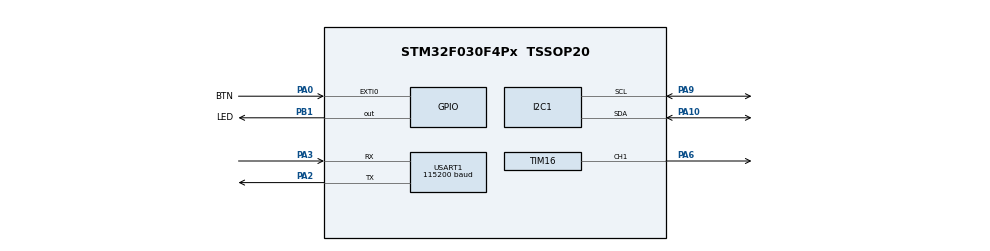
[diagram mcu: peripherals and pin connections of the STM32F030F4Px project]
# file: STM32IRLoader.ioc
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Dma.Request0=TIM16_CH1/UP
Dma.TIM16_CH1/UP.0.Direction=DMA_MEMORY_TO_PERIPH
Dma.TIM16_CH1/UP.0.Instance=DMA1_Channel3
Dma.TIM16_CH1/UP.0.MemDataAlignment=DMA_MDATAALIGN_BYTE
Dma.TIM16_CH1/UP.0.MemInc=DMA_MINC_ENABLE
Dma.TIM16_CH1/UP.0.Mode=DMA_NORMAL
Dma.TIM16_CH1/UP.0.PeriphDataAlignment=DMA_PDATAALIGN_WORD
Dma.TIM16_CH1/UP.0.PeriphInc=DMA_PINC_DISABLE
Dma.TIM16_CH1/UP.0.Priority=DMA_PRIORITY_LOW
I2C1.Timing=0x00201D2B
Mcu.Family=STM32F0
Mcu.Name=STM32F030F4Px
Mcu.Package=TSSOP20
NVIC.DMA1_Channel2_3_IRQn=true\:0\:0\:false\:false\:true\:false\:true\:true
NVIC.EXTI0_1_IRQn=true\:0\:0\:false\:false\:true\:true\:true\:true
PA0.GPIO_Label=BTN
PA0.GPIO_ModeDefaultEXTI=GPIO_MODE_IT_RISING_FALLING
PA0.Signal=GPXTI0
PA10.Mode=I2C
PA10.Signal=I2C1_SDA
PA2.Mode=Asynchronous
PA2.Signal=USART1_TX
PA3.Mode=Asynchronous
PA3.Signal=USART1_RX
PA6.Signal=S_TIM16_CH1
PA9.Mode=I2C
PA9.Signal=I2C1_SCL
PB1.GPIO_Label=LED
PB1.Signal=GPIO_Output
ProjectManager.HeapSize=0x200
ProjectManager.StackSize=0x400
ProjectManager.TargetToolchain=CMake
SH.S_TIM16_CH1.0=TIM16_CH1,PWM Generation1 CH1
TIM16.Channel=TIM_CHANNEL_1
TIM16.OCPolarity_1=TIM_OCPOLARITY_LOW
TIM16.Period=210
TIM16.Prescaler=0
TIM16.Pulse=210
USART1.BaudRate=115200
USART1.VirtualMode-Asynchronous=VM_ASYNC
VP_TIM16_VS_ClockSourceINT.Mode=Enable_Timer
board=custom

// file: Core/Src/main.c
/* USER CODE BEGIN Header */
/**
  ******************************************************************************
  * @file           : main.c
  * @brief          : Main program body
  ******************************************************************************
  * @attention
  *
  * Copyright (c) 2025 STMicroelectronics.
  * All rights reserved.
  *
  * This software is licensed under terms that can be found in the LICENSE file
  * in the root directory of this software component.
  * If no LICENSE file comes with this software, it is provided AS-IS.
  *
  ******************************************************************************
  */
/* USER CODE END Header */
#include "main.h"

/* USER CODE BEGIN Includes */

#include <stdio.h>

#include "IRPayload.h"
#include "stm32f0xx_hal_cortex.h"
#include "stm32f0xx_hal_dma.h"
#include "stm32f0xx_hal_flash.h"
#include "stm32f0xx_hal_gpio.h"
#include "stm32f0xx_hal_rcc_ex.h"
#include "stm32f0xx_hal_uart.h"
#include "stm32_hal_legacy.h"

/* USER CODE END Includes */

/* USER CODE BEGIN PD */

void writeSerial(const char * str);

/* USER CODE END PD */

I2C_HandleTypeDef hi2c1;

TIM_HandleTypeDef htim16;
DMA_HandleTypeDef hdma_tim16_ch1_up;

UART_HandleTypeDef huart1;

void SystemClock_Config(void);
static void MX_GPIO_Init(void);
static void MX_DMA_Init(void);
static void MX_I2C1_Init(void);
static void MX_USART1_UART_Init(void);
static void MX_TIM16_Init(void);

int main(void)
{

  /* MCU Configuration--------------------------------------------------------*/

  /* Reset of all peripherals, Initializes the Flash interface and the Systick. */
  HAL_Init();

  /* Configure the system clock */
  SystemClock_Config();

  /* Initialize all configured peripherals */
  MX_GPIO_Init();
  MX_DMA_Init();
  MX_I2C1_Init();
  MX_USART1_UART_Init();
  MX_TIM16_Init();
  /* USER CODE BEGIN 2 */
  // writeSerial("Reading EEPROM...\r\n");
  // writeSerial("Page 0, address 0\r\n");
  //
  // uint8_t deviceAddress = 0xA0;
  // uint8_t page = 0x01;
  // uint8_t payload[255];
  // uint8_t payloadLength = readIRPayload(&hi2c1, deviceAddress, page, payload);
  //
  // uint8_t payloadDMALength = payloadLength * 2;
  // uint8_t payloadDMA[payloadDMALength];
  // uint8_t alternate = 0; // 0 → 0, 1 → 250
  //
  // for (uint8_t i = 0; i < payloadLength; i++)
  // {
  //   payloadDMA[2 * i]     = payload[i];
  //   payloadDMA[2 * i + 1] = alternate ? 70 : 0;
  //
  //   alternate ^= 1; // bascule 0 ↔ 1
  // }
  //
  // HAL_TIM_DMABurst_MultiWriteStart(&htim16, TIM_DMABASE_RCR, TIM_DMA_UPDATE, payloadDMA, TIM_DMABurstLength_2Transfers, payloadDMALength);
  // HAL_TIM_PWM_Start(&htim16, TIM_CHANNEL_1);

  // --- From here, the payload is stored in "payload"

  /* USER CODE END 2 */

  /* Infinite loop */
  while (1)
  {

  }
}

void SystemClock_Config(void)
{
  RCC_OscInitTypeDef RCC_OscInitStruct = {0};
  RCC_ClkInitTypeDef RCC_ClkInitStruct = {0};
  RCC_PeriphCLKInitTypeDef PeriphClkInit = {0};

  /** Initializes the RCC Oscillators according to the specified parameters
  * in the RCC_OscInitTypeDef structure.
  */
  RCC_OscInitStruct.OscillatorType = RCC_OSCILLATORTYPE_HSI;
  RCC_OscInitStruct.HSIState = RCC_HSI_ON;
  RCC_OscInitStruct.HSICalibrationValue = RCC_HSICALIBRATION_DEFAULT;
  RCC_OscInitStruct.PLL.PLLState = RCC_PLL_NONE;
  if (HAL_RCC_OscConfig(&RCC_OscInitStruct) != HAL_OK)
  {
    Error_Handler();
  }

  /** Initializes the CPU, AHB and APB buses clocks
  */
  RCC_ClkInitStruct.ClockType = RCC_CLOCKTYPE_HCLK|RCC_CLOCKTYPE_SYSCLK
                              |RCC_CLOCKTYPE_PCLK1;
  RCC_ClkInitStruct.SYSCLKSource = RCC_SYSCLKSOURCE_HSI;
  RCC_ClkInitStruct.AHBCLKDivider = RCC_SYSCLK_DIV1;
  RCC_ClkInitStruct.APB1CLKDivider = RCC_HCLK_DIV1;

  if (HAL_RCC_ClockConfig(&RCC_ClkInitStruct, FLASH_LATENCY_0) != HAL_OK)
  {
    Error_Handler();
  }
  PeriphClkInit.PeriphClockSelection = RCC_PERIPHCLK_USART1|RCC_PERIPHCLK_I2C1;
  PeriphClkInit.Usart1ClockSelection = RCC_USART1CLKSOURCE_PCLK1;
  PeriphClkInit.I2c1ClockSelection = RCC_I2C1CLKSOURCE_HSI;
  if (HAL_RCCEx_PeriphCLKConfig(&PeriphClkInit) != HAL_OK)
  {
    Error_Handler();
  }
}

static void MX_I2C1_Init(void)
{

  hi2c1.Instance = I2C1;
  hi2c1.Init.Timing = 0x00201D2B;
  hi2c1.Init.OwnAddress1 = 0;
  hi2c1.Init.AddressingMode = I2C_ADDRESSINGMODE_7BIT;
  hi2c1.Init.DualAddressMode = I2C_DUALADDRESS_DISABLE;
  hi2c1.Init.OwnAddress2 = 0;
  hi2c1.Init.OwnAddress2Masks = I2C_OA2_NOMASK;
  hi2c1.Init.GeneralCallMode = I2C_GENERALCALL_DISABLE;
  hi2c1.Init.NoStretchMode = I2C_NOSTRETCH_DISABLE;
  if (HAL_I2C_Init(&hi2c1) != HAL_OK)
  {
    Error_Handler();
  }

  /** Configure Analogue filter
  */
  if (HAL_I2CEx_ConfigAnalogFilter(&hi2c1, I2C_ANALOGFILTER_ENABLE) != HAL_OK)
  {
    Error_Handler();
  }

  /** Configure Digital filter
  */
  if (HAL_I2CEx_ConfigDigitalFilter(&hi2c1, 0) != HAL_OK)
  {
    Error_Handler();
  }

}

static void MX_TIM16_Init(void)
{

  TIM_OC_InitTypeDef sConfigOC = {0};
  TIM_BreakDeadTimeConfigTypeDef sBreakDeadTimeConfig = {0};

  htim16.Instance = TIM16;
  htim16.Init.Prescaler = 0;
  htim16.Init.CounterMode = TIM_COUNTERMODE_UP;
  htim16.Init.Period = 210;
  htim16.Init.ClockDivision = TIM_CLOCKDIVISION_DIV1;
  htim16.Init.RepetitionCounter = 0;
  htim16.Init.AutoReloadPreload = TIM_AUTORELOAD_PRELOAD_DISABLE;
  if (HAL_TIM_Base_Init(&htim16) != HAL_OK)
  {
    Error_Handler();
  }
  if (HAL_TIM_PWM_Init(&htim16) != HAL_OK)
  {
    Error_Handler();
  }
  sConfigOC.OCMode = TIM_OCMODE_PWM1;
  sConfigOC.Pulse = 210;
  sConfigOC.OCPolarity = TIM_OCPOLARITY_LOW;
  sConfigOC.OCNPolarity = TIM_OCNPOLARITY_HIGH;
  sConfigOC.OCFastMode = TIM_OCFAST_DISABLE;
  sConfigOC.OCIdleState = TIM_OCIDLESTATE_RESET;
  sConfigOC.OCNIdleState = TIM_OCNIDLESTATE_RESET;
  if (HAL_TIM_PWM_ConfigChannel(&htim16, &sConfigOC, TIM_CHANNEL_1) != HAL_OK)
  {
    Error_Handler();
  }
  sBreakDeadTimeConfig.OffStateRunMode = TIM_OSSR_DISABLE;
  sBreakDeadTimeConfig.OffStateIDLEMode = TIM_OSSI_DISABLE;
  sBreakDeadTimeConfig.LockLevel = TIM_LOCKLEVEL_OFF;
  sBreakDeadTimeConfig.DeadTime = 0;
  sBreakDeadTimeConfig.BreakState = TIM_BREAK_DISABLE;
  sBreakDeadTimeConfig.BreakPolarity = TIM_BREAKPOLARITY_HIGH;
  sBreakDeadTimeConfig.AutomaticOutput = TIM_AUTOMATICOUTPUT_DISABLE;
  if (HAL_TIMEx_ConfigBreakDeadTime(&htim16, &sBreakDeadTimeConfig) != HAL_OK)
  {
    Error_Handler();
  }
  HAL_TIM_MspPostInit(&htim16);

}

static void MX_USART1_UART_Init(void)
{

  huart1.Instance = USART1;
  huart1.Init.BaudRate = 115200;
  huart1.Init.WordLength = UART_WORDLENGTH_8B;
  huart1.Init.StopBits = UART_STOPBITS_1;
  huart1.Init.Parity = UART_PARITY_NONE;
  huart1.Init.Mode = UART_MODE_TX_RX;
  huart1.Init.HwFlowCtl = UART_HWCONTROL_NONE;
  huart1.Init.OverSampling = UART_OVERSAMPLING_16;
  huart1.Init.OneBitSampling = UART_ONE_BIT_SAMPLE_DISABLE;
  huart1.AdvancedInit.AdvFeatureInit = UART_ADVFEATURE_NO_INIT;
  if (HAL_UART_Init(&huart1) != HAL_OK)
  {
    Error_Handler();
  }

}

static void MX_DMA_Init(void)
{

  /* DMA controller clock enable */
  __HAL_RCC_DMA1_CLK_ENABLE();

  /* DMA interrupt init */
  /* DMA1_Channel2_3_IRQn interrupt configuration */
  HAL_NVIC_SetPriority(DMA1_Channel2_3_IRQn, 0, 0);
  HAL_NVIC_EnableIRQ(DMA1_Channel2_3_IRQn);

}

static void MX_GPIO_Init(void)
{
  GPIO_InitTypeDef GPIO_InitStruct = {0};

  /* GPIO Ports Clock Enable */
  __HAL_RCC_GPIOA_CLK_ENABLE();
  __HAL_RCC_GPIOB_CLK_ENABLE();

  /*Configure GPIO pin Output Level */
  HAL_GPIO_WritePin(LED_GPIO_Port, LED_Pin, GPIO_PIN_RESET);

  /*Configure GPIO pin : BTN_Pin */
  GPIO_InitStruct.Pin = BTN_Pin;
  GPIO_InitStruct.Mode = GPIO_MODE_IT_RISING_FALLING;
  GPIO_InitStruct.Pull = GPIO_NOPULL;
  HAL_GPIO_Init(BTN_GPIO_Port, &GPIO_InitStruct);

  /*Configure GPIO pin : LED_Pin */
  GPIO_InitStruct.Pin = LED_Pin;
  GPIO_InitStruct.Mode = GPIO_MODE_OUTPUT_PP;
  GPIO_InitStruct.Pull = GPIO_NOPULL;
  GPIO_InitStruct.Speed = GPIO_SPEED_FREQ_LOW;
  HAL_GPIO_Init(LED_GPIO_Port, &GPIO_InitStruct);

  /* EXTI interrupt init*/
  HAL_NVIC_SetPriority(EXTI0_1_IRQn, 0, 0);
  HAL_NVIC_EnableIRQ(EXTI0_1_IRQn);

}

/* USER CODE BEGIN 4 */

void writeSerial(const char * str) {
  uint8_t MSG[35] = {'\0'};
  sprintf(MSG, str);
  HAL_UART_Transmit(&huart1, MSG, sizeof(MSG), 100);
}

/* USER CODE END 4 */

void Error_Handler(void)
{
  __disable_irq();
  while (1)
  {
  }
}
